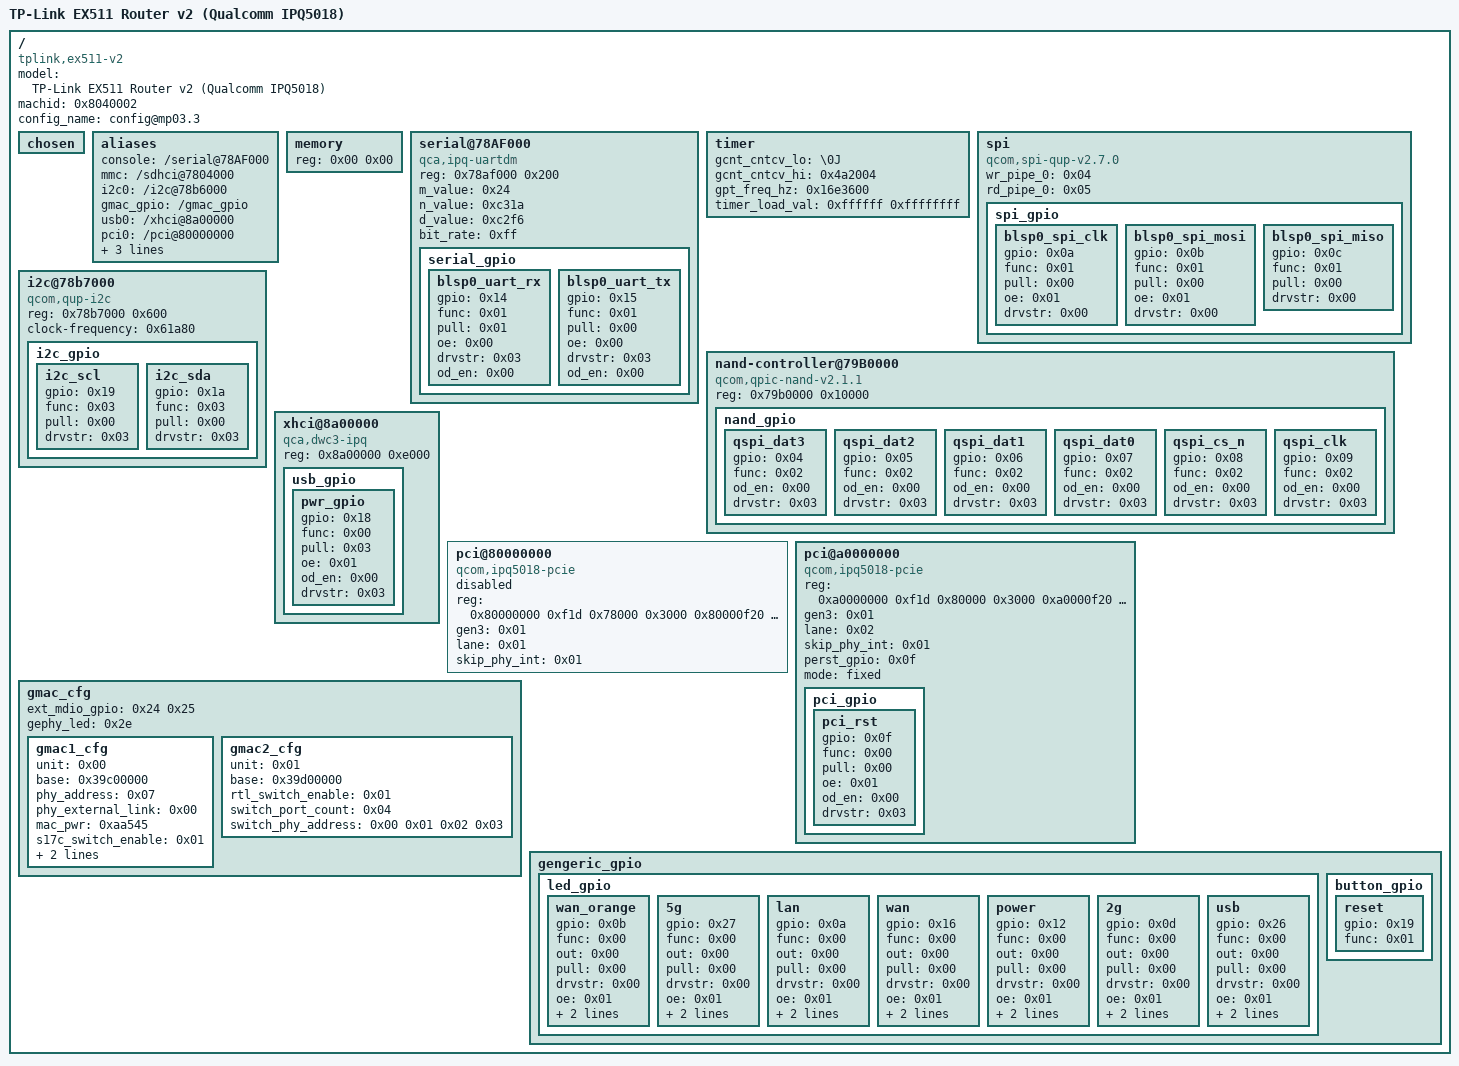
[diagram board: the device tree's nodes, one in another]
/dts-v1/;

/ {
	#address-cells = <0x01>;
	#size-cells = <0x01>;
/* From the Orignal Extracted DTS file
	model = "QCA, IPQ5018-MP03.3";
	compatible = "qca,ipq5018\0qca,ipq5018-mp03.3";
*/
    compatible = "tplink,ex511-v2", "qcom,gcc-ipq5018";
    model = "TP-Link EX511 Router v2 (Qualcomm IPQ5018)";
	machid = <0x8040002>;
	config_name = "config@mp03.3";

	chosen {
	};

	aliases {
		console = "/serial@78AF000";
		mmc = "/sdhci@7804000";
		i2c0 = "/i2c@78b6000";
		gmac_gpio = "/gmac_gpio";
		usb0 = "/xhci@8a00000";
		pci0 = "/pci@80000000";
		pci1 = "/pci@a0000000";
		nand = "/nand-controller@79B0000";
		gengeric_gpio = "/gengeric_gpio";
	};

	memory {
		device_type = "memory";
		reg = <0x00 0x00>;
	};

	serial@78AF000 {
		compatible = "qca,ipq-uartdm";
		reg = <0x78af000 0x200>;
		m_value = <0x24>;
		n_value = <0xc31a>;
		d_value = <0xc2f6>;
		bit_rate = <0xff>;
		status = "ok";

		serial_gpio {

			blsp0_uart_rx {
				gpio = <0x14>;
				func = <0x01>;
				pull = <0x01>;
				oe = <0x00>;
				drvstr = <0x03>;
				od_en = <0x00>;
			};

			blsp0_uart_tx {
				gpio = <0x15>;
				func = <0x01>;
				pull = <0x00>;
				oe = <0x00>;
				drvstr = <0x03>;
				od_en = <0x00>;
			};
		};
	};

	timer {
		gcnt_cntcv_lo = "\0J ";
		gcnt_cntcv_hi = <0x4a2004>;
		gpt_freq_hz = <0x16e3600>;
		timer_load_val = <0xffffff 0xffffffff>;
	};

	spi {
		compatible = "qcom,spi-qup-v2.7.0";
		wr_pipe_0 = <0x04>;
		rd_pipe_0 = <0x05>;
		status = "ok";

		spi_gpio {

			blsp0_spi_clk {
				gpio = <0x0a>;
				func = <0x01>;
				pull = <0x00>;
				oe = <0x01>;
				drvstr = <0x00>;
			};

			blsp0_spi_mosi {
				gpio = <0x0b>;
				func = <0x01>;
				pull = <0x00>;
				oe = <0x01>;
				drvstr = <0x00>;
			};

			blsp0_spi_miso {
				gpio = <0x0c>;
				func = <0x01>;
				pull = <0x00>;
				drvstr = <0x00>;
			};
		};
	};

	nand-controller@79B0000 {
		#address-cells = <0x01>;
		#size-cells = <0x00>;
		compatible = "qcom,qpic-nand-v2.1.1";
		reg = <0x79b0000 0x10000>;
		status = "okay";

		nand_gpio {

			qspi_dat3 {
				gpio = <0x04>;
				func = <0x02>;
				od_en = <0x00>;
				drvstr = <0x03>;
			};

			qspi_dat2 {
				gpio = <0x05>;
				func = <0x02>;
				od_en = <0x00>;
				drvstr = <0x03>;
			};

			qspi_dat1 {
				gpio = <0x06>;
				func = <0x02>;
				od_en = <0x00>;
				drvstr = <0x03>;
			};

			qspi_dat0 {
				gpio = <0x07>;
				func = <0x02>;
				od_en = <0x00>;
				drvstr = <0x03>;
			};

			qspi_cs_n {
				gpio = <0x08>;
				func = <0x02>;
				od_en = <0x00>;
				drvstr = <0x03>;
			};

			qspi_clk {
				gpio = <0x09>;
				func = <0x02>;
				od_en = <0x00>;
				drvstr = <0x03>;
			};
		};
	};

	i2c@78b7000 {
		compatible = "qcom,qup-i2c";
		#address-cells = <0x01>;
		#size-cells = <0x00>;
		reg = <0x78b7000 0x600>;
		clock-frequency = <0x61a80>;

		i2c_gpio {

			i2c_scl {
				gpio = <0x19>;
				func = <0x03>;
				pull = <0x00>;
				drvstr = <0x03>;
			};

			i2c_sda {
				gpio = <0x1a>;
				func = <0x03>;
				pull = <0x00>;
				drvstr = <0x03>;
			};
		};
	};

	xhci@8a00000 {
		compatible = "qca,dwc3-ipq";
		#address-cells = <0x01>;
		#size-cells = <0x01>;
		reg = <0x8a00000 0xe000>;

		usb_gpio {

			pwr_gpio {
				gpio = <0x18>;
				func = <0x00>;
				pull = <0x03>;
				oe = <0x01>;
				od_en = <0x00>;
				drvstr = <0x03>;
			};
		};
	};

	pci@80000000 {
		compatible = "qcom,ipq5018-pcie";
		#address-cells = <0x01>;
		#size-cells = <0x01>;
		reg = <0x80000000 0xf1d 0x78000 0x3000 0x80000f20 0xa8 0x80001000 0x1000 0x80300000 0xd00000 0x80100000 0x100000 0x1875004 0x40 0x7e000 0x800>;
		reg-names = "pci_dbi\0parf\0elbi\0dm_iatu\0axi_bars\0axi_conf\0pci_rst\0pci_phy";
		gen3 = <0x01>;
		lane = <0x01>;
		status = "disabled";
		skip_phy_int = <0x01>;
	};

	pci@a0000000 {
		compatible = "qcom,ipq5018-pcie";
		#address-cells = <0x01>;
		#size-cells = <0x01>;
		reg = <0xa0000000 0xf1d 0x80000 0x3000 0xa0000f20 0xa8 0xa0001000 0x1000 0xa0300000 0xd00000 0xa0100000 0x100000 0x1876004 0x40 0x86000 0x1000>;
		reg-names = "pci_dbi\0parf\0elbi\0dm_iatu\0axi_bars\0axi_conf\0pci_rst\0pci_phy";
		gen3 = <0x01>;
		lane = <0x02>;
		status = "ok";
		skip_phy_int = <0x01>;
		perst_gpio = <0x0f>;
		mode = "fixed";

		pci_gpio {

			pci_rst {
				gpio = <0x0f>;
				func = <0x00>;
				pull = <0x00>;
				oe = <0x01>;
				od_en = <0x00>;
				drvstr = <0x03>;
			};
		};
	};

	gmac_cfg {
		ext_mdio_gpio = <0x24 0x25>;
		gephy_led = <0x2e>;

		gmac1_cfg {
			unit = <0x00>;
			base = <0x39c00000>;
			phy_address = <0x07>;
			phy_external_link = <0x00>;
			mac_pwr = <0xaa545>;
			s17c_switch_enable = <0x01>;
			switch_port_count = <0x04>;
			switch_phy_address = <0x00 0x01 0x02 0x03>;
		};

		gmac2_cfg {
			unit = <0x01>;
			base = <0x39d00000>;
			rtl_switch_enable = <0x01>;
			switch_port_count = <0x04>;
			switch_phy_address = <0x00 0x01 0x02 0x03>;
		};
	};

	gengeric_gpio {

		led_gpio {

			wan_orange {
				gpio = <0x0b>;
				func = <0x00>;
				out = <0x00>;
				pull = <0x00>;
				drvstr = <0x00>;
				oe = <0x01>;
				od_en = <0x00>;
				pu_res = <0x02>;
			};

			5g {
				gpio = <0x27>;
				func = <0x00>;
				out = <0x00>;
				pull = <0x00>;
				drvstr = <0x00>;
				oe = <0x01>;
				od_en = <0x00>;
				pu_res = <0x02>;
			};

			lan {
				gpio = <0x0a>;
				func = <0x00>;
				out = <0x00>;
				pull = <0x00>;
				drvstr = <0x00>;
				oe = <0x01>;
				od_en = <0x00>;
				pu_res = <0x02>;
			};

			wan {
				gpio = <0x16>;
				func = <0x00>;
				out = <0x00>;
				pull = <0x00>;
				drvstr = <0x00>;
				oe = <0x01>;
				od_en = <0x00>;
				pu_res = <0x02>;
			};

			power {
				gpio = <0x12>;
				func = <0x00>;
				out = <0x00>;
				pull = <0x00>;
				drvstr = <0x00>;
				oe = <0x01>;
				od_en = <0x00>;
				pu_res = <0x02>;
			};

			2g {
				gpio = <0x0d>;
				func = <0x00>;
				out = <0x00>;
				pull = <0x00>;
				drvstr = <0x00>;
				oe = <0x01>;
				od_en = <0x00>;
				pu_res = <0x02>;
			};

			usb {
				gpio = <0x26>;
				func = <0x00>;
				out = <0x00>;
				pull = <0x00>;
				drvstr = <0x00>;
				oe = <0x01>;
				od_en = <0x00>;
				pu_res = <0x02>;
			};
		};

		button_gpio {

			reset {
				gpio = <0x19>;
				func = <0x01>;
			};
		};
	};
};
